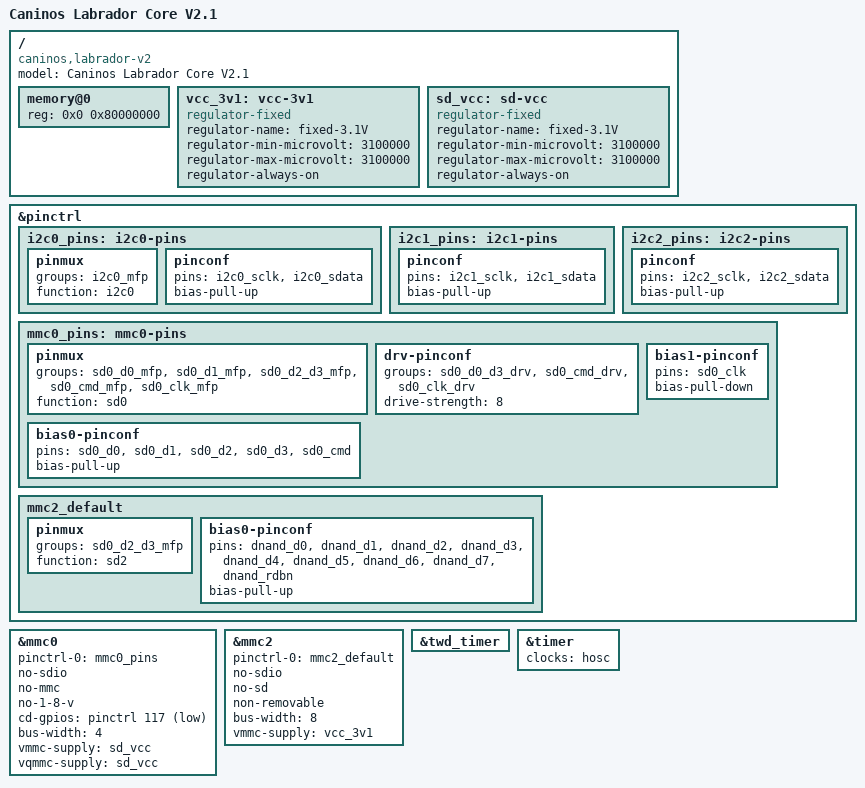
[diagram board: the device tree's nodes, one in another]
// SPDX-License-Identifier: (GPL-2.0+ OR MIT)
/*
 * Caninos Labrador SoM V2
 *
 * Copyright (c) 2019-2020 Matheus Castello
 */

#include "owl-s500.dtsi"

/ {
	model = "Caninos Labrador Core V2.1";
	compatible = "caninos,labrador-v2", "actions,s500";

	memory@0 {
		device_type = "memory";
		reg = <0x0 0x80000000>;
	};

	/* Fixed regulator used in the absence of PMIC */
	vcc_3v1: vcc-3v1 {
		compatible = "regulator-fixed";
		regulator-name = "fixed-3.1V";
		regulator-min-microvolt = <3100000>;
		regulator-max-microvolt = <3100000>;
		regulator-always-on;
	};

	/* Fixed regulator used in the absence of PMIC */
	sd_vcc: sd-vcc {
		compatible = "regulator-fixed";
		regulator-name = "fixed-3.1V";
		regulator-min-microvolt = <3100000>;
		regulator-max-microvolt = <3100000>;
		regulator-always-on;
	};
};

&pinctrl {
	i2c0_pins: i2c0-pins {
		pinmux {
			groups = "i2c0_mfp";
			function = "i2c0";
		};

		pinconf {
			pins = "i2c0_sclk", "i2c0_sdata";
			bias-pull-up;
		};
	};

	i2c1_pins: i2c1-pins {
		pinconf {
			pins = "i2c1_sclk", "i2c1_sdata";
			bias-pull-up;
		};
	};

	i2c2_pins: i2c2-pins {
		pinconf {
			pins = "i2c2_sclk", "i2c2_sdata";
			bias-pull-up;
		};
	};

	mmc0_pins: mmc0-pins {
		pinmux {
			groups = "sd0_d0_mfp", "sd0_d1_mfp", "sd0_d2_d3_mfp",
				 "sd0_cmd_mfp", "sd0_clk_mfp";
			function = "sd0";
		};

		drv-pinconf {
			groups = "sd0_d0_d3_drv", "sd0_cmd_drv", "sd0_clk_drv";
			drive-strength = <8>;
		};

		bias0-pinconf {
			pins = "sd0_d0", "sd0_d1", "sd0_d2",
			       "sd0_d3", "sd0_cmd";
			bias-pull-up;
		};

		bias1-pinconf {
			pins = "sd0_clk";
			bias-pull-down;
		};
	};

	mmc2_default: mmc2_default {
		pinmux {
			groups = "sd0_d2_d3_mfp";
			function = "sd2";
		};

		bias0-pinconf {
			pins = "dnand_d0", "dnand_d1", "dnand_d2", "dnand_d3",
                         	"dnand_d4", "dnand_d5", "dnand_d6", "dnand_d7",
			       	"dnand_rdbn";
			bias-pull-up;
		};
	};
};

/* uSD */
&mmc0 {
	status = "okay";
	pinctrl-names = "default";
	pinctrl-0 = <&mmc0_pins>;
	no-sdio;
	no-mmc;
	no-1-8-v;
	cd-gpios = <&pinctrl 117 GPIO_ACTIVE_LOW>;
	bus-width = <4>;
	vmmc-supply = <&sd_vcc>;
	vqmmc-supply = <&sd_vcc>;
};

/* eMMC */
&mmc2 {
	status = "okay";
	pinctrl-names = "default";
	pinctrl-0 = <&mmc2_default>;
	no-sdio;
	no-sd;
	non-removable;
	bus-width = <8>;
	vmmc-supply = <&vcc_3v1>;
};

&twd_timer {
	status = "okay";
};

&timer {
	clocks = <&hosc>;
};
